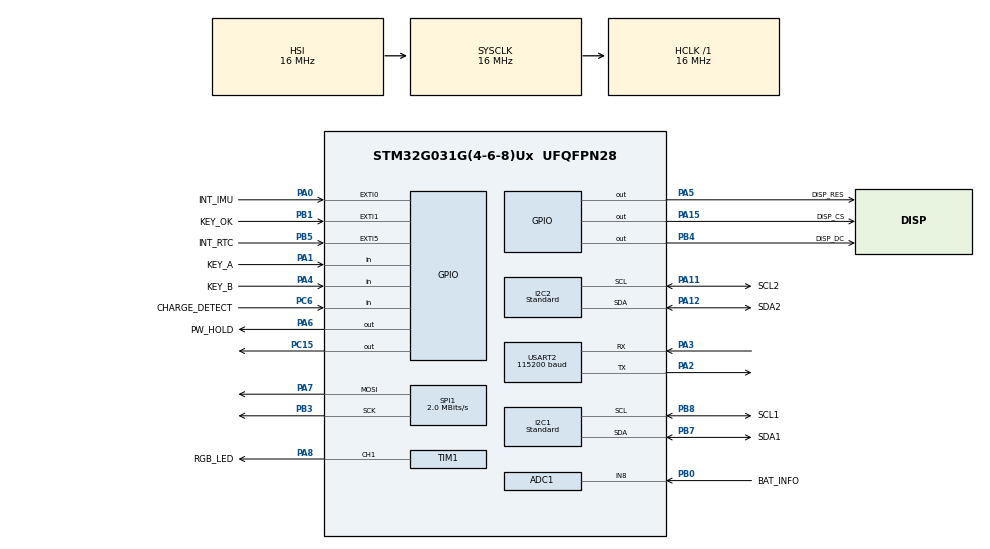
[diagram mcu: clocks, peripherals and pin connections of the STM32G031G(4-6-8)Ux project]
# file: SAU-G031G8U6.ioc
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ADC1.Channel-1\#ChannelRegularConversion=ADC_CHANNEL_8
ADC1.ClockPrescaler=ADC_CLOCK_SYNC_PCLK_DIV2
ADC1.ContinuousConvMode=ENABLE
ADC1.DMAContinuousRequests=ENABLE
ADC1.EOCSelection=ADC_EOC_SEQ_CONV
ADC1.NbrOfConversion=1
ADC1.NbrOfConversionFlag=1
ADC1.Overrun=ADC_OVR_DATA_PRESERVED
ADC1.OversamplingMode=ENABLE
ADC1.Rank-1\#ChannelRegularConversion=1
ADC1.Ratio=ADC_OVERSAMPLING_RATIO_256
ADC1.Resolution=ADC_RESOLUTION_12B
ADC1.RightBitShift=ADC_RIGHTBITSHIFT_4
ADC1.SamplingTime-1\#ChannelRegularConversion=ADC_SAMPLINGTIME_COMMON_1
ADC1.SamplingTimeCommon1=ADC_SAMPLETIME_39CYCLES_5
ADC1.SamplingTimeCommon2=ADC_SAMPLETIME_39CYCLES_5
ADC1.SelectedChannel=ADC_CHANNEL_8
ADC1.TriggerFrequencyMode=ADC_TRIGGER_FREQ_LOW
ADC1.master=1
Dma.ADC1.2.Direction=DMA_PERIPH_TO_MEMORY
Dma.ADC1.2.EventEnable=DISABLE
Dma.ADC1.2.Instance=DMA1_Channel3
Dma.ADC1.2.MemDataAlignment=DMA_MDATAALIGN_HALFWORD
Dma.ADC1.2.MemInc=DMA_MINC_ENABLE
Dma.ADC1.2.Mode=DMA_CIRCULAR
Dma.ADC1.2.PeriphDataAlignment=DMA_PDATAALIGN_HALFWORD
Dma.ADC1.2.PeriphInc=DMA_PINC_DISABLE
Dma.ADC1.2.Polarity=HAL_DMAMUX_REQ_GEN_RISING
Dma.ADC1.2.Priority=DMA_PRIORITY_MEDIUM
Dma.ADC1.2.RequestNumber=1
Dma.ADC1.2.SignalID=NONE
Dma.ADC1.2.SyncEnable=DISABLE
Dma.ADC1.2.SyncPolarity=HAL_DMAMUX_SYNC_NO_EVENT
Dma.ADC1.2.SyncRequestNumber=1
Dma.ADC1.2.SyncSignalID=NONE
Dma.Request0=USART2_RX
Dma.Request1=USART2_TX
Dma.Request2=ADC1
Dma.Request3=TIM1_CH1
Dma.TIM1_CH1.3.Direction=DMA_MEMORY_TO_PERIPH
Dma.TIM1_CH1.3.EventEnable=DISABLE
Dma.TIM1_CH1.3.Instance=DMA1_Channel4
Dma.TIM1_CH1.3.MemDataAlignment=DMA_MDATAALIGN_BYTE
Dma.TIM1_CH1.3.MemInc=DMA_MINC_ENABLE
Dma.TIM1_CH1.3.Mode=DMA_CIRCULAR
Dma.TIM1_CH1.3.PeriphDataAlignment=DMA_PDATAALIGN_WORD
Dma.TIM1_CH1.3.PeriphInc=DMA_PINC_DISABLE
Dma.TIM1_CH1.3.Polarity=HAL_DMAMUX_REQ_GEN_RISING
Dma.TIM1_CH1.3.Priority=DMA_PRIORITY_HIGH
Dma.TIM1_CH1.3.RequestNumber=1
Dma.TIM1_CH1.3.SignalID=NONE
Dma.TIM1_CH1.3.SyncEnable=DISABLE
Dma.TIM1_CH1.3.SyncPolarity=HAL_DMAMUX_SYNC_NO_EVENT
Dma.TIM1_CH1.3.SyncRequestNumber=1
Dma.TIM1_CH1.3.SyncSignalID=NONE
Dma.USART2_RX.0.Direction=DMA_PERIPH_TO_MEMORY
Dma.USART2_RX.0.EventEnable=DISABLE
Dma.USART2_RX.0.Instance=DMA1_Channel1
Dma.USART2_RX.0.MemDataAlignment=DMA_MDATAALIGN_BYTE
Dma.USART2_RX.0.MemInc=DMA_MINC_ENABLE
Dma.USART2_RX.0.Mode=DMA_NORMAL
Dma.USART2_RX.0.PeriphDataAlignment=DMA_PDATAALIGN_BYTE
Dma.USART2_RX.0.PeriphInc=DMA_PINC_DISABLE
Dma.USART2_RX.0.Polarity=HAL_DMAMUX_REQ_GEN_RISING
Dma.USART2_RX.0.Priority=DMA_PRIORITY_LOW
Dma.USART2_RX.0.RequestNumber=1
Dma.USART2_RX.0.SignalID=NONE
Dma.USART2_RX.0.SyncEnable=DISABLE
Dma.USART2_RX.0.SyncPolarity=HAL_DMAMUX_SYNC_NO_EVENT
Dma.USART2_RX.0.SyncRequestNumber=1
Dma.USART2_RX.0.SyncSignalID=NONE
Dma.USART2_TX.1.Direction=DMA_MEMORY_TO_PERIPH
Dma.USART2_TX.1.EventEnable=DISABLE
Dma.USART2_TX.1.Instance=DMA1_Channel2
Dma.USART2_TX.1.MemDataAlignment=DMA_MDATAALIGN_BYTE
Dma.USART2_TX.1.MemInc=DMA_MINC_ENABLE
Dma.USART2_TX.1.Mode=DMA_NORMAL
Dma.USART2_TX.1.PeriphDataAlignment=DMA_PDATAALIGN_BYTE
Dma.USART2_TX.1.PeriphInc=DMA_PINC_DISABLE
Dma.USART2_TX.1.Polarity=HAL_DMAMUX_REQ_GEN_RISING
Dma.USART2_TX.1.Priority=DMA_PRIORITY_LOW
Dma.USART2_TX.1.RequestNumber=1
Dma.USART2_TX.1.SignalID=NONE
Dma.USART2_TX.1.SyncEnable=DISABLE
Dma.USART2_TX.1.SyncPolarity=HAL_DMAMUX_SYNC_NO_EVENT
Dma.USART2_TX.1.SyncRequestNumber=1
Dma.USART2_TX.1.SyncSignalID=NONE
I2C1.I2C_Speed_Mode=I2C_Standard
I2C1.Timing=0x00303D5B
I2C2.I2C_Speed_Mode=I2C_Standard
Mcu.Family=STM32G0
Mcu.Name=STM32G031G(4-6-8)Ux
Mcu.Package=UFQFPN28
NVIC.ADC1_IRQn=true\:2\:0\:true\:false\:true\:true\:true
NVIC.DMA1_Ch4_5_DMAMUX1_OVR_IRQn=true\:1\:0\:true\:false\:true\:false\:true
NVIC.DMA1_Channel1_IRQn=true\:3\:0\:true\:false\:true\:false\:true
NVIC.DMA1_Channel2_3_IRQn=true\:3\:0\:true\:false\:true\:false\:true
NVIC.EXTI0_1_IRQn=true\:2\:0\:true\:false\:true\:true\:true
NVIC.EXTI4_15_IRQn=true\:2\:0\:true\:false\:true\:true\:true
NVIC.TIM17_IRQn=true\:3\:0\:true\:false\:true\:false\:true
NVIC.TimeBase=TIM17_IRQn
NVIC.TimeBaseIP=TIM17
NVIC.USART2_IRQn=true\:2\:0\:true\:false\:true\:true\:true
PA0.GPIO_Label=INT_IMU
PA0.GPIO_ModeDefaultEXTI=GPIO_MODE_IT_FALLING
PA0.Signal=GPXTI0
PA1.GPIO_Label=KEY_A
PA1.GPIO_PuPd=GPIO_PULLUP
PA1.Signal=GPIO_Input
PA11\ [PA9].GPIO_Label=SCL2
PA11\ [PA9].Mode=I2C
PA11\ [PA9].Signal=I2C2_SCL
PA12\ [PA10].GPIO_Label=SDA2
PA12\ [PA10].Mode=I2C
PA12\ [PA10].Signal=I2C2_SDA
PA13.Mode=Serial_Wire
PA13.Signal=SYS_SWDIO
PA14-BOOT0.Mode=Serial_Wire
PA14-BOOT0.Signal=SYS_SWCLK
PA15.GPIO_Label=DISP_CS
PA15.Signal=GPIO_Output
PA2.Mode=Asynchronous
PA2.Signal=USART2_TX
PA3.Mode=Asynchronous
PA3.Signal=USART2_RX
PA4.GPIO_Label=KEY_B
PA4.GPIO_PuPd=GPIO_PULLUP
PA4.Signal=GPIO_Input
PA5.GPIO_Label=DISP_RES
PA5.Signal=GPIO_Output
PA6.GPIO_Label=PW_HOLD
PA6.Signal=GPIO_Output
PA7.Mode=TX_Only_Simplex_Unidirect_Master
PA7.Signal=SPI1_MOSI
PA8.GPIO_Label=RGB_LED
PA8.GPIO_PuPd=GPIO_PULLDOWN
PA8.GPIO_Speed=GPIO_SPEED_FREQ_LOW
PA8.Signal=S_TIM1_CH1
PB0.GPIO_Label=BAT_INFO
PB0.Mode=IN8
PB0.Signal=ADC1_IN8
PB1.GPIO_Label=KEY_OK
PB1.GPIO_ModeDefaultEXTI=GPIO_MODE_IT_FALLING
PB1.GPIO_PuPd=GPIO_PULLUP
PB1.Signal=GPXTI1
PB3.Mode=TX_Only_Simplex_Unidirect_Master
PB3.Signal=SPI1_SCK
PB4.GPIO_Label=DISP_DC
PB4.Signal=GPIO_Output
PB5.GPIO_Label=INT_RTC
PB5.GPIO_ModeDefaultEXTI=GPIO_MODE_IT_FALLING
PB5.GPIO_PuPd=GPIO_PULLUP
PB5.Signal=GPXTI5
PB7.GPIO_Label=SDA1
PB7.Mode=I2C
PB7.Signal=I2C1_SDA
PB8.GPIO_Label=SCL1
PB8.Mode=I2C
PB8.Signal=I2C1_SCL
PC14-OSC32_IN\ (PC14).Mode=HSE-External-Clock-Source
PC14-OSC32_IN\ (PC14).Signal=RCC_OSC_IN
PC15-OSC32_OUT\ (PC15).Signal=GPIO_Output
PC6.GPIO_Label=CHARGE_DETECT
PC6.GPIO_PuPd=GPIO_PULLUP
PC6.Signal=GPIO_Input
ProjectManager.HeapSize=0x400
ProjectManager.StackSize=0x400
ProjectManager.TargetToolchain=STM32CubeIDE
RCC.ADCFreq_Value=16000000
RCC.AHBFreq_Value=16000000
RCC.CortexFreq_Value=16000000
RCC.EXTERNAL_CLOCK_VALUE=12288000
RCC.HCLKFreq_Value=16000000
RCC.HSE_VALUE=8000000
RCC.HSI_VALUE=16000000
RCC.LSE_VALUE=32768
RCC.SYSCLKFreq_VALUE=16000000
RCC.VCOOutputFreq_Value=128000000
SH.S_TIM1_CH1.0=TIM1_CH1,PWM Generation1 CH1
SPI1.BaudRatePrescaler=SPI_BAUDRATEPRESCALER_8
SPI1.CalculateBaudRate=2.0 MBits/s
SPI1.Direction=SPI_DIRECTION_2LINES
SPI1.Mode=SPI_MODE_MASTER
SPI1.VirtualType=VM_MASTER
TIM1.Channel-PWM\ Generation1\ CH1=TIM_CHANNEL_1
TIM1.Period=20-1
USART2.BaudRate=115200
USART2.VirtualMode-Asynchronous=VM_ASYNC
VP_SYS_VS_tim17.Mode=TIM17
VP_TIM1_VS_ClockSourceINT.Mode=Internal
board=custom

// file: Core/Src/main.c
/* USER CODE BEGIN Header */
/**
  ******************************************************************************
  * @file           : main.c
  * @brief          : Main program body
  ******************************************************************************
  * @attention
  *
  * <h2><center>&copy; Copyright (c) 2022 STMicroelectronics.
  * All rights reserved.</center></h2>
  *
  * This software component is licensed by ST under BSD 3-Clause license,
  * the "License"; You may not use this file except in compliance with the
  * License. You may obtain a copy of the License at:
  *                        opensource.org/licenses/BSD-3-Clause
  *
  ******************************************************************************
  */
/* USER CODE END Header */
#include "main.h"
#include "adc.h"
#include "dma.h"
#include "i2c.h"
#include "spi.h"
#include "tim.h"
#include "usart.h"
#include "gpio.h"

/* USER CODE BEGIN Includes */
#include <stdio.h>	//提供c库函数printf重定向到USARTx
#include <string.h>
#include <stdarg.h>
#include "BSP.h"
#include "cppports.h"
/* USER CODE END Includes */

void SystemClock_Config(void);

int main(void)
{

  /* MCU Configuration--------------------------------------------------------*/

  /* Reset of all peripherals, Initializes the Flash interface and the Systick. */
  HAL_Init();

  /* Configure the system clock */
  SystemClock_Config();

  /* Initialize all configured peripherals */
  MX_GPIO_Init();
  MX_USART2_UART_Init();
  MX_DMA_Init();
  MX_SPI1_Init();
  MX_I2C2_Init();
  MX_I2C1_Init();
  MX_ADC1_Init();
  MX_TIM1_Init();
  /* USER CODE BEGIN 2 */
  preSetupInit();
  setup();
  /* USER CODE END 2 */

  /* Infinite loop */
  /* USER CODE BEGIN WHILE */
  while (1)
  {
	  loop();
    /* USER CODE END WHILE */

  }
}

void SystemClock_Config(void)
{
  RCC_OscInitTypeDef RCC_OscInitStruct = {0};
  RCC_ClkInitTypeDef RCC_ClkInitStruct = {0};
  RCC_PeriphCLKInitTypeDef PeriphClkInit = {0};

  /** Configure the main internal regulator output voltage
  */
  HAL_PWREx_ControlVoltageScaling(PWR_REGULATOR_VOLTAGE_SCALE1);
  /** Initializes the RCC Oscillators according to the specified parameters
  * in the RCC_OscInitTypeDef structure.
  */
  RCC_OscInitStruct.OscillatorType = RCC_OSCILLATORTYPE_HSI;
  RCC_OscInitStruct.HSIState = RCC_HSI_ON;
  RCC_OscInitStruct.HSIDiv = RCC_HSI_DIV1;
  RCC_OscInitStruct.HSICalibrationValue = RCC_HSICALIBRATION_DEFAULT;
  RCC_OscInitStruct.PLL.PLLState = RCC_PLL_NONE;
  if (HAL_RCC_OscConfig(&RCC_OscInitStruct) != HAL_OK)
  {
    Error_Handler();
  }
  /** Initializes the CPU, AHB and APB buses clocks
  */
  RCC_ClkInitStruct.ClockType = RCC_CLOCKTYPE_HCLK|RCC_CLOCKTYPE_SYSCLK
                              |RCC_CLOCKTYPE_PCLK1;
  RCC_ClkInitStruct.SYSCLKSource = RCC_SYSCLKSOURCE_HSI;
  RCC_ClkInitStruct.AHBCLKDivider = RCC_SYSCLK_DIV1;
  RCC_ClkInitStruct.APB1CLKDivider = RCC_HCLK_DIV1;

  if (HAL_RCC_ClockConfig(&RCC_ClkInitStruct, FLASH_LATENCY_0) != HAL_OK)
  {
    Error_Handler();
  }
  /** Initializes the peripherals clocks
  */
  PeriphClkInit.PeriphClockSelection = RCC_PERIPHCLK_I2C1|RCC_PERIPHCLK_ADC
                              |RCC_PERIPHCLK_TIM1;
  PeriphClkInit.I2c1ClockSelection = RCC_I2C1CLKSOURCE_PCLK1;
  PeriphClkInit.AdcClockSelection = RCC_ADCCLKSOURCE_SYSCLK;
  PeriphClkInit.Tim1ClockSelection = RCC_TIM1CLKSOURCE_PCLK1;
  if (HAL_RCCEx_PeriphCLKConfig(&PeriphClkInit) != HAL_OK)
  {
    Error_Handler();
  }
}

/* USER CODE BEGIN 4 */
void EXT_I2C1_Init(){
	MX_I2C1_Init();
}

/* USER CODE END 4 */

void HAL_TIM_PeriodElapsedCallback(TIM_HandleTypeDef *htim)
{
  if (htim->Instance == TIM17) {
    HAL_IncTick();
  }
}

void Error_Handler(void)
{
  __disable_irq();
  while (1)
  {
  }
}

/************************ (C) COPYRIGHT STMicroelectronics *****END OF FILE****/
